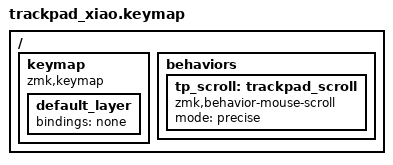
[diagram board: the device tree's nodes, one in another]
#include <behaviors.dtsi>
#include <dt-bindings/zmk/keys.h>
#include <dt-bindings/zmk/mouse.h>

/ {
    keymap {
        compatible = "zmk,keymap";
        
        default_layer {
            bindings = <
                &none  // No physical keys, trackpad handles input
            >;
        };
    };

    // Optional: Custom behaviors for trackpad gestures
    behaviors {
        tp_scroll: trackpad_scroll {
            compatible = "zmk,behavior-mouse-scroll";
            #binding-cells = <0>;
            mode = "precise";
        };
    };
};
